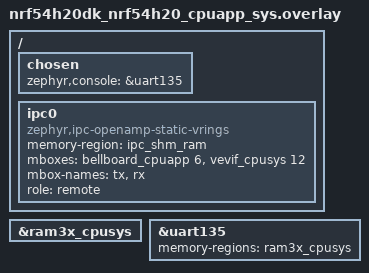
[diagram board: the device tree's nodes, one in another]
/*
 * Copyright (c) 2022 Nordic Semiconductor ASA
 *
 * SPDX-License-Identifier: Apache-2.0
 */

#include <common/nordic_nrf_next/nrfx_ram3x_dma.dtsi>
#include "../../boards/shared/nrf54_ipc_shm_ram2sys.dtsi"

/ {
	chosen {
		 zephyr,console = &uart135;
	};

	ipc0: ipc0 {
		compatible = "zephyr,ipc-openamp-static-vrings";
		memory-region = <&ipc_shm_ram>;
		mboxes = <&bellboard_cpuapp 6>,
			 <&vevif_cpusys 12>;
		mbox-names = "tx", "rx";
		role = "remote";
		status = "okay";
	};
};

&ram3x_cpusys {
	status = "okay";
};

&uart135 {
	status = "okay";
	memory-regions = <&ram3x_cpusys>;
};
